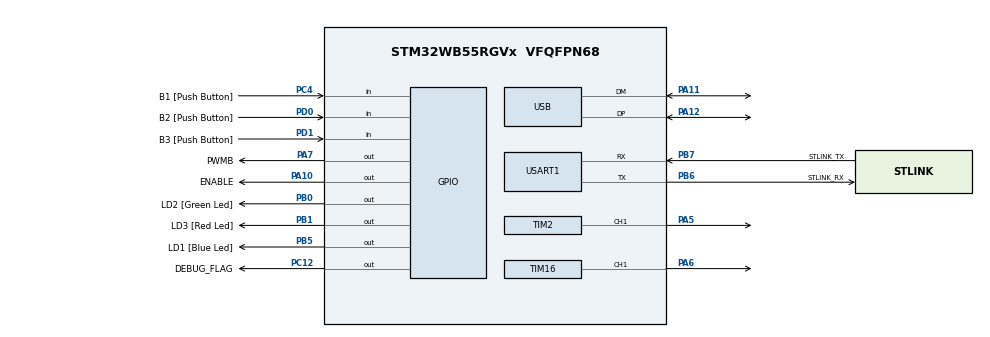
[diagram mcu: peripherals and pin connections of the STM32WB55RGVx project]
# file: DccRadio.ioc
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Dma.Request0=TIM2_CH1
Dma.TIM2_CH1.0.Direction=DMA_MEMORY_TO_PERIPH
Dma.TIM2_CH1.0.EventEnable=DISABLE
Dma.TIM2_CH1.0.Instance=DMA1_Channel1
Dma.TIM2_CH1.0.MemDataAlignment=DMA_MDATAALIGN_HALFWORD
Dma.TIM2_CH1.0.MemInc=DMA_MINC_ENABLE
Dma.TIM2_CH1.0.Mode=DMA_NORMAL
Dma.TIM2_CH1.0.PeriphDataAlignment=DMA_PDATAALIGN_HALFWORD
Dma.TIM2_CH1.0.PeriphInc=DMA_PINC_DISABLE
Dma.TIM2_CH1.0.Polarity=HAL_DMAMUX_REQ_GEN_RISING
Dma.TIM2_CH1.0.Priority=DMA_PRIORITY_LOW
Dma.TIM2_CH1.0.RequestNumber=1
Dma.TIM2_CH1.0.SignalID=NONE
Dma.TIM2_CH1.0.SyncEnable=DISABLE
Dma.TIM2_CH1.0.SyncPolarity=HAL_DMAMUX_SYNC_NO_EVENT
Dma.TIM2_CH1.0.SyncRequestNumber=1
Dma.TIM2_CH1.0.SyncSignalID=NONE
LPTIM1.ClockPrescaler=LPTIM_PRESCALER_DIV128
Mcu.Family=STM32WB
Mcu.Name=STM32WB55RGVx
Mcu.Package=VFQFPN68
NVIC.DMA1_Channel1_IRQn=true\:0\:0\:false\:false\:true\:false\:true
NVIC.LPTIM1_IRQn=true\:0\:0\:false\:false\:true\:true\:true
NVIC.PriorityGroup=NVIC_PRIORITYGROUP_4
NVIC.TIM1_TRG_COM_TIM17_IRQn=true\:0\:0\:false\:false\:true\:true\:true
NVIC.USB_LP_IRQn=true\:0\:0\:false\:false\:true\:false\:true
OSC_IN.Mode=HSE-External-Oscillator
OSC_IN.Signal=RCC_OSC_IN
OSC_OUT.Mode=HSE-External-Oscillator
OSC_OUT.Signal=RCC_OSC_OUT
PA10.GPIO_Label=ENABLE
PA10.Signal=GPIO_Output
PA11.Mode=Device
PA11.Signal=USB_DM
PA12.Mode=Device
PA12.Signal=USB_DP
PA13.GPIO_Label=JTMS
PA13.Mode=Trace_Asynchronous_SW
PA13.Signal=SYS_JTMS-SWDIO
PA14.GPIO_Label=JTCK
PA14.Mode=Trace_Asynchronous_SW
PA14.Signal=SYS_JTCK-SWCLK
PA5.Signal=S_TIM2_CH1
PA6.Signal=S_TIM16_CH1
PA7.GPIO_Label=PWMB
PA7.Signal=GPIO_Output
PB0.GPIO_Label=LD2 [Green Led]
PB0.Signal=GPIO_Output
PB1.GPIO_Label=LD3 [Red Led]
PB1.Signal=GPIO_Output
PB3.GPIO_Label=JTDO
PB3.Mode=Trace_Asynchronous_SW
PB3.Signal=SYS_JTDO-SWO
PB5.GPIO_Label=LD1 [Blue Led]
PB5.Signal=GPIO_Output
PB6.GPIO_Label=STLINK_RX
PB6.GPIO_PuPd=GPIO_PULLUP
PB6.Mode=Asynchronous
PB6.Signal=USART1_TX
PB7.GPIO_Label=STLINK_TX
PB7.GPIO_PuPd=GPIO_PULLUP
PB7.Mode=Asynchronous
PB7.Signal=USART1_RX
PC12.GPIO_Label=DEBUG_FLAG
PC12.Signal=GPIO_Output
PC13.Mode=SYS_WakeUp1
PC13.Signal=SYS_WKUP2
PC14-OSC32_IN.Mode=LSE-External-Oscillator
PC14-OSC32_IN.Signal=RCC_OSC32_IN
PC15-OSC32_OUT.Mode=LSE-External-Oscillator
PC15-OSC32_OUT.Signal=RCC_OSC32_OUT
PC4.GPIO_Label=B1 [Push Button]
PC4.Signal=GPIO_Input
PD0.GPIO_Label=B2 [Push Button]
PD0.Signal=GPIO_Input
PD1.GPIO_Label=B3 [Push Button]
PD1.Signal=GPIO_Input
ProjectManager.HeapSize=0x200
ProjectManager.StackSize=0x400
ProjectManager.TargetToolchain=STM32CubeIDE
RCC.ADCFreq_Value=48000000
RCC.AHB2CLKDivider=RCC_SYSCLK_DIV2
RCC.AHBFreq_Value=64000000
RCC.APB1Freq_Value=64000000
RCC.APB1TimFreq_Value=64000000
RCC.APB2Freq_Value=64000000
RCC.APB2TimFreq_Value=64000000
RCC.APB3Freq_Value=16000000
RCC.CortexFreq_Value=64000000
RCC.HCLKFreq_Value=64000000
RCC.HSE_VALUE=32000000
RCC.HSI48_VALUE=48000000
RCC.HSI_VALUE=16000000
RCC.PLLN=32
RCC.PLLSAI1N=24
RCC.SMPSCLockSelectionVirtual=RCC_SMPSCLKSOURCE_HSI
RCC.SMPSCLockSelectionVirtualVirtual=RCC_SMPSCLKSOURCE_HSI
RCC.SMPSDivider=1
RCC.SYSCLKFreq_VALUE=64000000
RCC.SYSCLKSource=RCC_SYSCLKSOURCE_PLLCLK
RCC.USBFreq_Value=48000000
RCC.VCOOutputFreq_Value=128000000
SH.S_TIM16_CH1.0=TIM16_CH1,PWM Generation1 CH1
SH.S_TIM2_CH1.0=TIM2_CH1,PWM Generation1 CH1
TIM16.Channel=TIM_CHANNEL_1
TIM16.Period=112
TIM16.Prescaler=32
TIM16.Pulse=56
TIM17.Period=840
TIM17.Prescaler=64
TIM2.Channel-PWM\ Generation1\ CH1=TIM_CHANNEL_1
TIM2.OCPolarity_1=TIM_OCPOLARITY_LOW
TIM2.Period=112
TIM2.Prescaler=32
TIM2.Pulse-PWM\ Generation1\ CH1=56
USART1.VirtualMode-Asynchronous=VM_ASYNC
USART1.WordLength=WORDLENGTH_7B
USB_DEVICE.CLASS_NAME_FS=CDC
USB_DEVICE.VirtualMode=Cdc
USB_DEVICE.VirtualModeFS=Cdc_FS
VP_LPTIM1_VS_LPTIM_counterModeInternalClock.Mode=Counts__internal_clock_event_00
VP_TIM16_VS_ClockSourceINT.Mode=Enable_Timer
VP_TIM17_VS_ClockSourceINT.Mode=Enable_Timer
VP_TIM2_VS_ClockSourceINT.Mode=Internal
VP_USB_DEVICE_VS_USB_DEVICE_CDC_FS.Mode=CDC_FS
board=P-NUCLEO-WB55-Nucleo

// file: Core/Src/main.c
/* USER CODE BEGIN Header */
/**
  ******************************************************************************
  * @file           : main.c
  * @brief          : Main program body
  ******************************************************************************
  * @attention
  *
  * <h2><center>&copy; Copyright (c) 2020 STMicroelectronics.
  * All rights reserved.</center></h2>
  *
  * This software component is licensed by ST under BSD 3-Clause license,
  * the "License"; You may not use this file except in compliance with the
  * License. You may obtain a copy of the License at:
  *                        opensource.org/licenses/BSD-3-Clause
  *
  ******************************************************************************
  */
/* USER CODE END Header */

#include "main.h"
#include "usb_device.h"

/* USER CODE BEGIN Includes */
#include "Dcc/DccGlobal.h"

/* USER CODE END Includes */

LPTIM_HandleTypeDef hlptim1;

TIM_HandleTypeDef htim2;
TIM_HandleTypeDef htim16;
TIM_HandleTypeDef htim17;
DMA_HandleTypeDef hdma_tim2_ch1;

UART_HandleTypeDef huart1;

/* USER CODE BEGIN PV */

uint32_t		valid_dcc_command_sent = 0;
/* USER CODE END PV */

void SystemClock_Config(void);
static void MX_GPIO_Init(void);
static void MX_DMA_Init(void);
static void MX_USART1_UART_Init(void);
static void MX_TIM2_Init(void);
static void MX_TIM16_Init(void);
static void MX_TIM17_Init(void);
static void MX_LPTIM1_Init(void);

int main(void)
{

  /* MCU Configuration--------------------------------------------------------*/

  /* Reset of all peripherals, Initializes the Flash interface and the Systick. */
  HAL_Init();

  /* Configure the system clock */
  SystemClock_Config();

  /* Initialize all configured peripherals */
  MX_GPIO_Init();
  MX_DMA_Init();
  MX_USART1_UART_Init();
  MX_TIM2_Init();
  MX_TIM16_Init();
  MX_USB_Device_Init();
  MX_TIM17_Init();
  MX_LPTIM1_Init();
  /* USER CODE BEGIN 2 */
  InitDccPackets();
  main_track.main_power = 0;
  DccStart();
  HAL_LPTIM_Counter_Start_IT(&hlptim1, LPTIM1_PERIOD);
  USBD_CDC_Init();
  /* USER CODE END 2 */

  /* Infinite loop */
  /* USER CODE BEGIN WHILE */
  while (1)
  {
		if ( main_track.main_power == 1 )
			DCC_ACTIVE_LED_PORT->BSRR = DCC_ACTIVE_LED_PIN;	// Set pin
		else
			DCC_ACTIVE_LED_PORT->BRR  = DCC_ACTIVE_LED_PIN;	// Clear pin
		if ( USB_UART_RxCpltCallback() == 1 )
			DccParser();

    /* USER CODE END WHILE */

  }
}

void SystemClock_Config(void)
{
  RCC_OscInitTypeDef RCC_OscInitStruct = {0};
  RCC_ClkInitTypeDef RCC_ClkInitStruct = {0};
  RCC_PeriphCLKInitTypeDef PeriphClkInitStruct = {0};

  /** Configure LSE Drive Capability
  */
  HAL_PWR_EnableBkUpAccess();
  __HAL_RCC_LSEDRIVE_CONFIG(RCC_LSEDRIVE_LOW);
  /** Configure the main internal regulator output voltage
  */
  __HAL_PWR_VOLTAGESCALING_CONFIG(PWR_REGULATOR_VOLTAGE_SCALE1);
  /** Initializes the CPU, AHB and APB busses clocks
  */
  RCC_OscInitStruct.OscillatorType = RCC_OSCILLATORTYPE_HSI|RCC_OSCILLATORTYPE_HSE
                              |RCC_OSCILLATORTYPE_LSE|RCC_OSCILLATORTYPE_MSI;
  RCC_OscInitStruct.HSEState = RCC_HSE_ON;
  RCC_OscInitStruct.LSEState = RCC_LSE_ON;
  RCC_OscInitStruct.HSIState = RCC_HSI_ON;
  RCC_OscInitStruct.MSIState = RCC_MSI_ON;
  RCC_OscInitStruct.HSICalibrationValue = RCC_HSICALIBRATION_DEFAULT;
  RCC_OscInitStruct.MSICalibrationValue = RCC_MSICALIBRATION_DEFAULT;
  RCC_OscInitStruct.MSIClockRange = RCC_MSIRANGE_6;
  RCC_OscInitStruct.PLL.PLLState = RCC_PLL_ON;
  RCC_OscInitStruct.PLL.PLLSource = RCC_PLLSOURCE_MSI;
  RCC_OscInitStruct.PLL.PLLM = RCC_PLLM_DIV1;
  RCC_OscInitStruct.PLL.PLLN = 32;
  RCC_OscInitStruct.PLL.PLLP = RCC_PLLP_DIV2;
  RCC_OscInitStruct.PLL.PLLR = RCC_PLLR_DIV2;
  RCC_OscInitStruct.PLL.PLLQ = RCC_PLLQ_DIV2;
  if (HAL_RCC_OscConfig(&RCC_OscInitStruct) != HAL_OK)
  {
    Error_Handler();
  }
  /** Configure the SYSCLKSource, HCLK, PCLK1 and PCLK2 clocks dividers
  */
  RCC_ClkInitStruct.ClockType = RCC_CLOCKTYPE_HCLK4|RCC_CLOCKTYPE_HCLK2
                              |RCC_CLOCKTYPE_HCLK|RCC_CLOCKTYPE_SYSCLK
                              |RCC_CLOCKTYPE_PCLK1|RCC_CLOCKTYPE_PCLK2;
  RCC_ClkInitStruct.SYSCLKSource = RCC_SYSCLKSOURCE_PLLCLK;
  RCC_ClkInitStruct.AHBCLKDivider = RCC_SYSCLK_DIV1;
  RCC_ClkInitStruct.APB1CLKDivider = RCC_HCLK_DIV1;
  RCC_ClkInitStruct.APB2CLKDivider = RCC_HCLK_DIV1;
  RCC_ClkInitStruct.AHBCLK2Divider = RCC_SYSCLK_DIV2;
  RCC_ClkInitStruct.AHBCLK4Divider = RCC_SYSCLK_DIV1;

  if (HAL_RCC_ClockConfig(&RCC_ClkInitStruct, FLASH_LATENCY_3) != HAL_OK)
  {
    Error_Handler();
  }
  /** Initializes the peripherals clocks
  */
  PeriphClkInitStruct.PeriphClockSelection = RCC_PERIPHCLK_SMPS|RCC_PERIPHCLK_USART1
                              |RCC_PERIPHCLK_LPTIM1|RCC_PERIPHCLK_USB;
  PeriphClkInitStruct.PLLSAI1.PLLN = 24;
  PeriphClkInitStruct.PLLSAI1.PLLP = RCC_PLLP_DIV2;
  PeriphClkInitStruct.PLLSAI1.PLLQ = RCC_PLLQ_DIV2;
  PeriphClkInitStruct.PLLSAI1.PLLR = RCC_PLLR_DIV2;
  PeriphClkInitStruct.PLLSAI1.PLLSAI1ClockOut = RCC_PLLSAI1_USBCLK;
  PeriphClkInitStruct.Usart1ClockSelection = RCC_USART1CLKSOURCE_PCLK2;
  PeriphClkInitStruct.Lptim1ClockSelection = RCC_LPTIM1CLKSOURCE_PCLK1;
  PeriphClkInitStruct.UsbClockSelection = RCC_USBCLKSOURCE_PLLSAI1;
  PeriphClkInitStruct.SmpsClockSelection = RCC_SMPSCLKSOURCE_HSI;
  PeriphClkInitStruct.SmpsDivSelection = RCC_SMPSCLKDIV_RANGE0;
  if (HAL_RCCEx_PeriphCLKConfig(&PeriphClkInitStruct) != HAL_OK)
  {
    Error_Handler();
  }
  /** Enable MSI Auto calibration
  */
  HAL_RCCEx_EnableMSIPLLMode();
}

static void MX_LPTIM1_Init(void)
{

  hlptim1.Instance = LPTIM1;
  hlptim1.Init.Clock.Source = LPTIM_CLOCKSOURCE_APBCLOCK_LPOSC;
  hlptim1.Init.Clock.Prescaler = LPTIM_PRESCALER_DIV128;
  hlptim1.Init.Trigger.Source = LPTIM_TRIGSOURCE_SOFTWARE;
  hlptim1.Init.OutputPolarity = LPTIM_OUTPUTPOLARITY_HIGH;
  hlptim1.Init.UpdateMode = LPTIM_UPDATE_IMMEDIATE;
  hlptim1.Init.CounterSource = LPTIM_COUNTERSOURCE_INTERNAL;
  hlptim1.Init.Input1Source = LPTIM_INPUT1SOURCE_GPIO;
  hlptim1.Init.Input2Source = LPTIM_INPUT2SOURCE_GPIO;
  if (HAL_LPTIM_Init(&hlptim1) != HAL_OK)
  {
    Error_Handler();
  }

}

static void MX_TIM2_Init(void)
{

  TIM_ClockConfigTypeDef sClockSourceConfig = {0};
  TIM_MasterConfigTypeDef sMasterConfig = {0};
  TIM_OC_InitTypeDef sConfigOC = {0};

  htim2.Instance = TIM2;
  htim2.Init.Prescaler = 32;
  htim2.Init.CounterMode = TIM_COUNTERMODE_UP;
  htim2.Init.Period = 112;
  htim2.Init.ClockDivision = TIM_CLOCKDIVISION_DIV1;
  htim2.Init.AutoReloadPreload = TIM_AUTORELOAD_PRELOAD_DISABLE;
  if (HAL_TIM_Base_Init(&htim2) != HAL_OK)
  {
    Error_Handler();
  }
  sClockSourceConfig.ClockSource = TIM_CLOCKSOURCE_INTERNAL;
  if (HAL_TIM_ConfigClockSource(&htim2, &sClockSourceConfig) != HAL_OK)
  {
    Error_Handler();
  }
  if (HAL_TIM_PWM_Init(&htim2) != HAL_OK)
  {
    Error_Handler();
  }
  sMasterConfig.MasterOutputTrigger = TIM_TRGO_RESET;
  sMasterConfig.MasterSlaveMode = TIM_MASTERSLAVEMODE_DISABLE;
  if (HAL_TIMEx_MasterConfigSynchronization(&htim2, &sMasterConfig) != HAL_OK)
  {
    Error_Handler();
  }
  sConfigOC.OCMode = TIM_OCMODE_PWM1;
  sConfigOC.Pulse = 56;
  sConfigOC.OCPolarity = TIM_OCPOLARITY_LOW;
  sConfigOC.OCFastMode = TIM_OCFAST_DISABLE;
  if (HAL_TIM_PWM_ConfigChannel(&htim2, &sConfigOC, TIM_CHANNEL_1) != HAL_OK)
  {
    Error_Handler();
  }
  HAL_TIM_MspPostInit(&htim2);

}

static void MX_TIM16_Init(void)
{

  TIM_OC_InitTypeDef sConfigOC = {0};
  TIM_BreakDeadTimeConfigTypeDef sBreakDeadTimeConfig = {0};

  htim16.Instance = TIM16;
  htim16.Init.Prescaler = 32;
  htim16.Init.CounterMode = TIM_COUNTERMODE_UP;
  htim16.Init.Period = 112;
  htim16.Init.ClockDivision = TIM_CLOCKDIVISION_DIV1;
  htim16.Init.RepetitionCounter = 0;
  htim16.Init.AutoReloadPreload = TIM_AUTORELOAD_PRELOAD_DISABLE;
  if (HAL_TIM_Base_Init(&htim16) != HAL_OK)
  {
    Error_Handler();
  }
  if (HAL_TIM_PWM_Init(&htim16) != HAL_OK)
  {
    Error_Handler();
  }
  sConfigOC.OCMode = TIM_OCMODE_PWM1;
  sConfigOC.Pulse = 56;
  sConfigOC.OCPolarity = TIM_OCPOLARITY_HIGH;
  sConfigOC.OCNPolarity = TIM_OCNPOLARITY_HIGH;
  sConfigOC.OCFastMode = TIM_OCFAST_DISABLE;
  sConfigOC.OCIdleState = TIM_OCIDLESTATE_RESET;
  sConfigOC.OCNIdleState = TIM_OCNIDLESTATE_RESET;
  if (HAL_TIM_PWM_ConfigChannel(&htim16, &sConfigOC, TIM_CHANNEL_1) != HAL_OK)
  {
    Error_Handler();
  }
  sBreakDeadTimeConfig.OffStateRunMode = TIM_OSSR_DISABLE;
  sBreakDeadTimeConfig.OffStateIDLEMode = TIM_OSSI_DISABLE;
  sBreakDeadTimeConfig.LockLevel = TIM_LOCKLEVEL_OFF;
  sBreakDeadTimeConfig.DeadTime = 0;
  sBreakDeadTimeConfig.BreakState = TIM_BREAK_DISABLE;
  sBreakDeadTimeConfig.BreakPolarity = TIM_BREAKPOLARITY_HIGH;
  sBreakDeadTimeConfig.BreakFilter = 0;
  sBreakDeadTimeConfig.AutomaticOutput = TIM_AUTOMATICOUTPUT_DISABLE;
  if (HAL_TIMEx_ConfigBreakDeadTime(&htim16, &sBreakDeadTimeConfig) != HAL_OK)
  {
    Error_Handler();
  }
  HAL_TIM_MspPostInit(&htim16);

}

static void MX_TIM17_Init(void)
{

  htim17.Instance = TIM17;
  htim17.Init.Prescaler = 64;
  htim17.Init.CounterMode = TIM_COUNTERMODE_UP;
  htim17.Init.Period = 840;
  htim17.Init.ClockDivision = TIM_CLOCKDIVISION_DIV1;
  htim17.Init.RepetitionCounter = 0;
  htim17.Init.AutoReloadPreload = TIM_AUTORELOAD_PRELOAD_DISABLE;
  if (HAL_TIM_Base_Init(&htim17) != HAL_OK)
  {
    Error_Handler();
  }

}

static void MX_USART1_UART_Init(void)
{

  huart1.Instance = USART1;
  huart1.Init.BaudRate = 115200;
  huart1.Init.WordLength = UART_WORDLENGTH_7B;
  huart1.Init.StopBits = UART_STOPBITS_1;
  huart1.Init.Parity = UART_PARITY_NONE;
  huart1.Init.Mode = UART_MODE_TX_RX;
  huart1.Init.HwFlowCtl = UART_HWCONTROL_NONE;
  huart1.Init.OverSampling = UART_OVERSAMPLING_16;
  huart1.Init.OneBitSampling = UART_ONE_BIT_SAMPLE_DISABLE;
  huart1.Init.ClockPrescaler = UART_PRESCALER_DIV1;
  huart1.AdvancedInit.AdvFeatureInit = UART_ADVFEATURE_NO_INIT;
  if (HAL_UART_Init(&huart1) != HAL_OK)
  {
    Error_Handler();
  }
  if (HAL_UARTEx_SetTxFifoThreshold(&huart1, UART_TXFIFO_THRESHOLD_1_8) != HAL_OK)
  {
    Error_Handler();
  }
  if (HAL_UARTEx_SetRxFifoThreshold(&huart1, UART_RXFIFO_THRESHOLD_1_8) != HAL_OK)
  {
    Error_Handler();
  }
  if (HAL_UARTEx_DisableFifoMode(&huart1) != HAL_OK)
  {
    Error_Handler();
  }

}

static void MX_DMA_Init(void)
{

  /* DMA controller clock enable */
  __HAL_RCC_DMAMUX1_CLK_ENABLE();
  __HAL_RCC_DMA1_CLK_ENABLE();

  /* DMA interrupt init */
  /* DMA1_Channel1_IRQn interrupt configuration */
  HAL_NVIC_SetPriority(DMA1_Channel1_IRQn, 0, 0);
  HAL_NVIC_EnableIRQ(DMA1_Channel1_IRQn);

}

static void MX_GPIO_Init(void)
{
  GPIO_InitTypeDef GPIO_InitStruct = {0};

  /* GPIO Ports Clock Enable */
  __HAL_RCC_GPIOC_CLK_ENABLE();
  __HAL_RCC_GPIOA_CLK_ENABLE();
  __HAL_RCC_GPIOB_CLK_ENABLE();
  __HAL_RCC_GPIOD_CLK_ENABLE();

  /*Configure GPIO pin Output Level */
  HAL_GPIO_WritePin(GPIOA, PWMB_Pin|ENABLE_Pin, GPIO_PIN_RESET);

  /*Configure GPIO pin Output Level */
  HAL_GPIO_WritePin(GPIOB, LD2_Pin|LD3_Pin|LD1_Pin, GPIO_PIN_RESET);

  /*Configure GPIO pin Output Level */
  HAL_GPIO_WritePin(DEBUG_FLAG_GPIO_Port, DEBUG_FLAG_Pin, GPIO_PIN_RESET);

  /*Configure GPIO pins : PWMB_Pin ENABLE_Pin */
  GPIO_InitStruct.Pin = PWMB_Pin|ENABLE_Pin;
  GPIO_InitStruct.Mode = GPIO_MODE_OUTPUT_PP;
  GPIO_InitStruct.Pull = GPIO_NOPULL;
  GPIO_InitStruct.Speed = GPIO_SPEED_FREQ_LOW;
  HAL_GPIO_Init(GPIOA, &GPIO_InitStruct);

  /*Configure GPIO pin : B1_Pin */
  GPIO_InitStruct.Pin = B1_Pin;
  GPIO_InitStruct.Mode = GPIO_MODE_INPUT;
  GPIO_InitStruct.Pull = GPIO_NOPULL;
  HAL_GPIO_Init(B1_GPIO_Port, &GPIO_InitStruct);

  /*Configure GPIO pins : LD2_Pin LD3_Pin LD1_Pin */
  GPIO_InitStruct.Pin = LD2_Pin|LD3_Pin|LD1_Pin;
  GPIO_InitStruct.Mode = GPIO_MODE_OUTPUT_PP;
  GPIO_InitStruct.Pull = GPIO_NOPULL;
  GPIO_InitStruct.Speed = GPIO_SPEED_FREQ_LOW;
  HAL_GPIO_Init(GPIOB, &GPIO_InitStruct);

  /*Configure GPIO pin : DEBUG_FLAG_Pin */
  GPIO_InitStruct.Pin = DEBUG_FLAG_Pin;
  GPIO_InitStruct.Mode = GPIO_MODE_OUTPUT_PP;
  GPIO_InitStruct.Pull = GPIO_NOPULL;
  GPIO_InitStruct.Speed = GPIO_SPEED_FREQ_LOW;
  HAL_GPIO_Init(DEBUG_FLAG_GPIO_Port, &GPIO_InitStruct);

  /*Configure GPIO pins : B2_Pin B3_Pin */
  GPIO_InitStruct.Pin = B2_Pin|B3_Pin;
  GPIO_InitStruct.Mode = GPIO_MODE_INPUT;
  GPIO_InitStruct.Pull = GPIO_NOPULL;
  HAL_GPIO_Init(GPIOD, &GPIO_InitStruct);

}

void Error_Handler(void)
{
}

/************************ (C) COPYRIGHT STMicroelectronics *****END OF FILE****/
